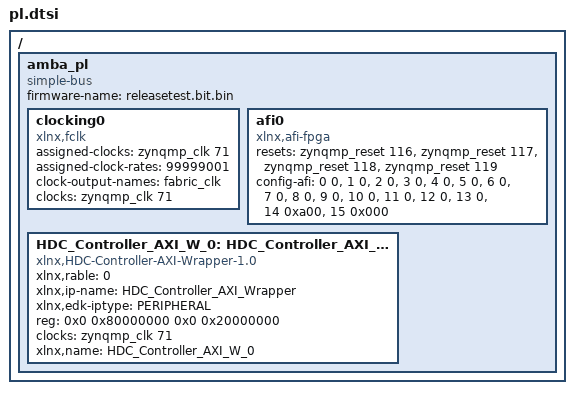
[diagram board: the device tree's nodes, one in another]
/ {
	amba_pl: amba_pl {
		ranges;
		compatible = "simple-bus";
		#address-cells = <2>;
		#size-cells = <2>;
		firmware-name = "releasetest.bit.bin";
		clocking0: clocking0 {
			compatible = "xlnx,fclk";
			status = "okay";
			assigned-clocks = <&zynqmp_clk 71>;
			assigned-clock-rates = <99999001>;
			#clock-cells = <0>;
			clock-output-names = "fabric_clk";
			clocks = <&zynqmp_clk 71>;
		};
		afi0: afi0 {
			status = "okay";
			compatible = "xlnx,afi-fpga";
			resets = <&zynqmp_reset 116>, <&zynqmp_reset 117>, <&zynqmp_reset 118>, <&zynqmp_reset 119>;
			config-afi = < 0 0>, <1 0>, <2 0>, <3 0>, <4 0>, <5 0>, <6 0>, <7 0>, <8 0>, <9 0>, <10 0>, <11 0>, <12 0>, <13 0>, <14 0xa00>, <15 0x000>;
		};
		HDC_Controller_AXI_W_0: HDC_Controller_AXI_Wrapper@80000000 {
			xlnx,rable = <0>;
			compatible = "xlnx,HDC-Controller-AXI-Wrapper-1.0";
			status = "okay";
			clock-names = "S_AXI_ACLK";
			xlnx,ip-name = "HDC_Controller_AXI_Wrapper";
			xlnx,edk-iptype = "PERIPHERAL";
			reg = <0x0 0x80000000 0x0 0x20000000>;
			clocks = <&zynqmp_clk 71>;
			xlnx,name = "HDC_Controller_AXI_W_0";
		};
	};
};
